AUTOSAR XML (schema 4-2-2)
package /Components
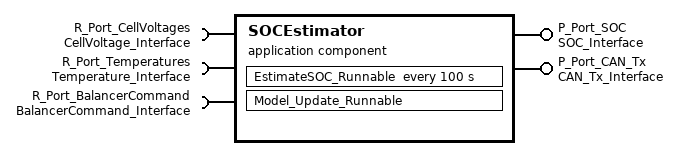
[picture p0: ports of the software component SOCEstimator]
  application sw component type SOCEstimator
    provide port P_Port_SOC: provided-interface=SOC_Interface
    provide port P_Port_CAN_Tx: provided-interface=CAN_Tx_Interface
    require port R_Port_CellVoltages: required-interface=CellVoltage_Interface
    require port R_Port_Temperatures: required-interface=Temperature_Interface
    require port R_Port_BalancerCommand: required-interface=BalancerCommand_Interface
    behavior SOCEstimator_Behavior
      data received event New_CellData: start-on-event=EstimateSOC_Runnable
      timing event Estimate_Period_100ms: start-on-event=EstimateSOC_Runnable, period=100
      runnable EstimateSOC_Runnable: minimum-start-interval=100, symbol=SOCEstimator_EstimateSOC
        data-receive-point-by-arguments:
          access CellVoltages_Arg: accessed-variable=R_Port_CellVoltages.cellVoltages
          access Temperatures_Arg: accessed-variable=R_Port_Temperatures.temperatures
        data-send-points:
          4 x access:
            Write_SOC: accessed-variable=P_Port_SOC.SOC
            Write_SOH: accessed-variable=P_Port_SOC.SOH
            Write_Confidence: accessed-variable=P_Port_SOC.confidence
            Send_CAN_Frame: accessed-variable=P_Port_CAN_Tx.CAN_Frame
        parameter access Est_Params: accessed-parameter=R_Port_CellVoltages.packVoltage
      runnable Model_Update_Runnable: minimum-start-interval=1000, symbol=SOCEstimator_ModelUpdate
        data-receive-point-by-arguments:
          access Model_Input_CellVoltages: accessed-variable=R_Port_CellVoltages.cellVoltages
        data-send-points:
          access Publish_ModelStatus: accessed-variable=P_Port_SOC.confidence
        parameter access Model_Calibration_Params: accessed-parameter=R_Port_Temperatures.hotspotIndex
